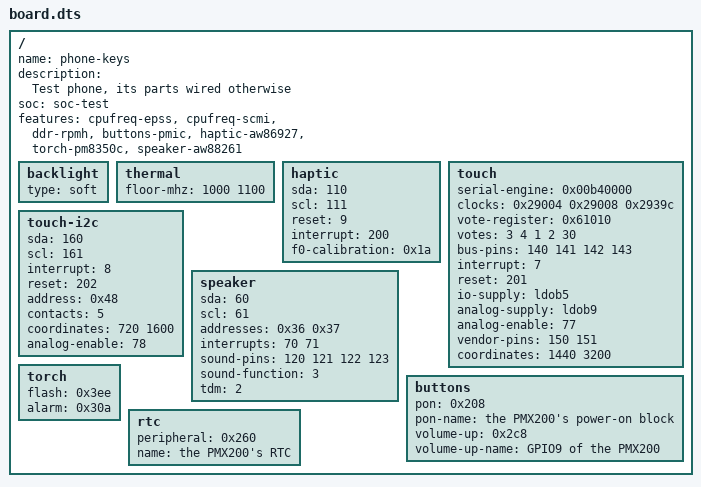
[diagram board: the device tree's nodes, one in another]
/dts-v1/;

// A test phone wired unlike the real ones, on a made-up chip (soc.dtsi beside this file): its keys on the
// third PMIC of the bus, volume up on its ninth GPIO, behind an arbiter that is elsewhere and that knows
// this system as its third; its flashlight, vibration motor, speaker amplifiers and touch controller on
// other pins, buses and serial engines than the first phones'. A value of the first phones that is still
// written into a driver shows here as a part that never answers, or a write that goes nowhere.
/ {
	name = "phone-keys";
	description = "Test phone, its parts wired otherwise";
	soc = "soc-test";

	features = "cpufreq-epss", "cpufreq-scmi", "ddr-rpmh", "buttons-pmic", "haptic-aw86927", "torch-pm8350c", "speaker-aw88261";

	backlight {
		type = "soft";
	};

	thermal {
		floor-mhz = <1000 1100>;
	};

	haptic {
		sda = <110>;
		scl = <111>;
		reset = <9>;
		interrupt = <200>;
		f0-calibration = <0x1a>;
	};

	// (a touch controller's wiring unlike either phone's: no driver is listed for it, the drivers' tests read it)
	touch {
		serial-engine = <0x00b40000>;
		clocks = <0x29004 0x29008 0x2939c>;
		vote-register = <0x61010>;
		votes = <3 4 1 2 30>;
		bus-pins = <140 141 142 143>;
		interrupt = <7>;
		reset = <201>;
		io-supply = "ldob5";
		analog-supply = "ldob9";
		analog-enable = <77>;
		vendor-pins = <150 151>;
		coordinates = <1440 3200>;     // (a larger panel than the first phones' 1080 x 2400)
	};

	// (a touch controller on I2C wired unlike phone-i2c's: five fingers, at another address, on other pins, its analog
	// supply behind a pin and nothing asked of RPMh; no driver is listed for it, the driver's test reads it)
	touch-i2c {
		sda = <160>;
		scl = <161>;
		interrupt = <8>;
		reset = <202>;
		address = <0x48>;
		contacts = <5>;
		coordinates = <720 1600>;
		analog-enable = <78>;
	};

	speaker {
		sda = <60>;
		scl = <61>;
		addresses = <0x36 0x37>;
		interrupts = <70 71>;
		sound-pins = <120 121 122 123>;
		sound-function = <3>;
		tdm = <2>;                      // the tertiary TDM interface: port 0x9020, group 0x9120, bit clock 0x204
	};

	// (its PM8350C is the bus's fourth chip, not the third)
	torch {
		flash = <0x3ee>;
		alarm = <0x30a>;
	};

	buttons {
		pon = <0x208>;                  // slave 2, registers 0x0800
		pon-name = "the PMX200's power-on block";
		volume-up = <0x2c8>;            // slave 2, registers 0xc800: GPIO9 of a pinctrl@c000
		volume-up-name = "GPIO9 of the PMX200";
	};

	// (its clock on the same third PMIC, at an older chip's place: registers 0x6000 of slave 2)
	rtc {
		peripheral = <0x260>;
		name = "the PMX200's RTC";
	};
};
